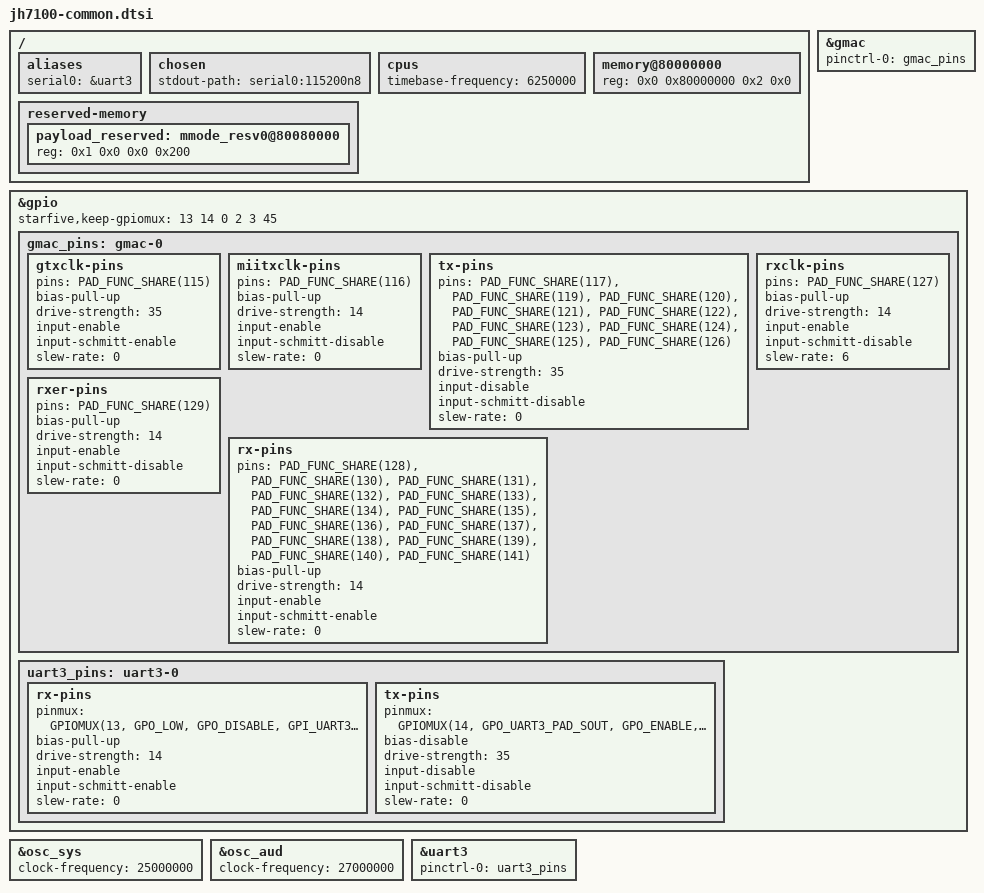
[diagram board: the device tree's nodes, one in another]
// SPDX-License-Identifier: GPL-2.0 OR MIT
/*
 * Copyright (C) 2021 StarFive Technology Co., Ltd.
 * Copyright (C) 2021 Emil Renner Berthing <kernel@esmil.dk>
 */

/dts-v1/;
#include "jh7100.dtsi"
#include <dt-bindings/gpio/gpio.h>
#include <dt-bindings/leds/common.h>
#include <dt-bindings/pinctrl/pinctrl-starfive.h>

#undef WM8960_ENABLED
#undef AC108_ENABLED

/ {
	aliases {
		serial0 = &uart3;
	};

	chosen {
		stdout-path = "serial0:115200n8";
	};

	cpus {
		timebase-frequency = <6250000>;
	};

	memory@80000000 {
		device_type = "memory";
		reg = <0x0 0x80000000 0x2 0x0>;
	};

    reserved-memory {
		#address-cells = <2>;
		#size-cells = <2>;
		ranges;

        payload_reserved: mmode_resv0@80080000 {
            reg = <0x1 0x0 0x0 0x200>;
        };
	};
};

&gmac {
	pinctrl-names = "default";
	pinctrl-0 = <&gmac_pins>;
	status = "okay";
};

&gpio {
	/* don't reset gpio mux for serial console on uart3 */
	starfive,keep-gpiomux = <13 14 0 2 3 45>;

	gmac_pins: gmac-0 {
		gtxclk-pins {
			pins = <PAD_FUNC_SHARE(115)>;
			bias-pull-up;
			drive-strength = <35>;
			input-enable;
			input-schmitt-enable;
			slew-rate = <0>;
		};
		miitxclk-pins {
			pins = <PAD_FUNC_SHARE(116)>;
			bias-pull-up;
			drive-strength = <14>;
			input-enable;
			input-schmitt-disable;
			slew-rate = <0>;
		};
		tx-pins {
			pins = <PAD_FUNC_SHARE(117)>,
			       <PAD_FUNC_SHARE(119)>,
			       <PAD_FUNC_SHARE(120)>,
			       <PAD_FUNC_SHARE(121)>,
			       <PAD_FUNC_SHARE(122)>,
			       <PAD_FUNC_SHARE(123)>,
			       <PAD_FUNC_SHARE(124)>,
			       <PAD_FUNC_SHARE(125)>,
			       <PAD_FUNC_SHARE(126)>;
			bias-pull-up;
			drive-strength = <35>;
			input-disable;
			input-schmitt-disable;
			slew-rate = <0>;
		};
		rxclk-pins {
			pins = <PAD_FUNC_SHARE(127)>;
			bias-pull-up;
			drive-strength = <14>;
			input-enable;
			input-schmitt-disable;
			slew-rate = <6>;
		};
		rxer-pins {
			pins = <PAD_FUNC_SHARE(129)>;
			bias-pull-up;
			drive-strength = <14>;
			input-enable;
			input-schmitt-disable;
			slew-rate = <0>;
		};
		rx-pins {
			pins = <PAD_FUNC_SHARE(128)>,
			       <PAD_FUNC_SHARE(130)>,
			       <PAD_FUNC_SHARE(131)>,
			       <PAD_FUNC_SHARE(132)>,
			       <PAD_FUNC_SHARE(133)>,
			       <PAD_FUNC_SHARE(134)>,
			       <PAD_FUNC_SHARE(135)>,
			       <PAD_FUNC_SHARE(136)>,
			       <PAD_FUNC_SHARE(137)>,
			       <PAD_FUNC_SHARE(138)>,
			       <PAD_FUNC_SHARE(139)>,
			       <PAD_FUNC_SHARE(140)>,
			       <PAD_FUNC_SHARE(141)>;
			bias-pull-up;
			drive-strength = <14>;
			input-enable;
			input-schmitt-enable;
			slew-rate = <0>;
		};
	};

	uart3_pins: uart3-0 {
		rx-pins {
			pinmux = <GPIOMUX(13, GPO_LOW, GPO_DISABLE,
				  GPI_UART3_PAD_SIN)>;
			bias-pull-up;
			drive-strength = <14>;
			input-enable;
			input-schmitt-enable;
			slew-rate = <0>;
		};
		tx-pins {
			pinmux = <GPIOMUX(14, GPO_UART3_PAD_SOUT,
				  GPO_ENABLE, GPI_NONE)>;
			bias-disable;
			drive-strength = <35>;
			input-disable;
			input-schmitt-disable;
			slew-rate = <0>;
		};
	};
};

&osc_sys {
	clock-frequency = <25000000>;
};

&osc_aud {
	clock-frequency = <27000000>;
};

&uart3 {
	pinctrl-names = "default";
	pinctrl-0 = <&uart3_pins>;
	status = "okay";
};
